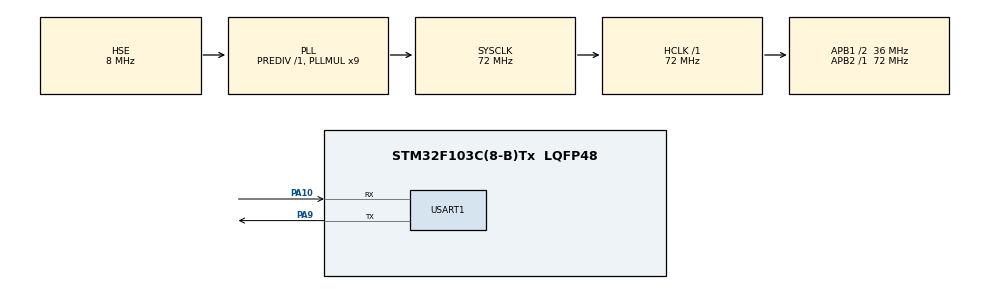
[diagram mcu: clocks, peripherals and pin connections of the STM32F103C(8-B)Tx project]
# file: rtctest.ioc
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Mcu.Family=STM32F1
Mcu.Name=STM32F103C(8-B)Tx
Mcu.Package=LQFP48
NVIC.PriorityGroup=NVIC_PRIORITYGROUP_4
PA10.Mode=Asynchronous
PA10.Signal=USART1_RX
PA13.Mode=Serial_Wire
PA13.Signal=SYS_JTMS-SWDIO
PA14.Mode=Serial_Wire
PA14.Signal=SYS_JTCK-SWCLK
PA9.Mode=Asynchronous
PA9.Signal=USART1_TX
PC14-OSC32_IN.Mode=LSE-External-Oscillator
PC14-OSC32_IN.Signal=RCC_OSC32_IN
PC15-OSC32_OUT.Mode=LSE-External-Oscillator
PC15-OSC32_OUT.Signal=RCC_OSC32_OUT
PD0-OSC_IN.Mode=HSE-External-Oscillator
PD0-OSC_IN.Signal=RCC_OSC_IN
PD1-OSC_OUT.Mode=HSE-External-Oscillator
PD1-OSC_OUT.Signal=RCC_OSC_OUT
ProjectManager.HeapSize=0x200
ProjectManager.StackSize=0x400
ProjectManager.TargetToolchain=STM32CubeIDE
RCC.AHBFreq_Value=72000000
RCC.APB1CLKDivider=RCC_HCLK_DIV2
RCC.APB1Freq_Value=36000000
RCC.APB1TimFreq_Value=72000000
RCC.APB2Freq_Value=72000000
RCC.APB2TimFreq_Value=72000000
RCC.HCLKFreq_Value=72000000
RCC.PLLMUL=RCC_PLL_MUL9
RCC.PLLSourceVirtual=RCC_PLLSOURCE_HSE
RCC.RTCClockSelection=RCC_RTCCLKSOURCE_LSE
RCC.SYSCLKFreq_VALUE=72000000
RCC.SYSCLKSource=RCC_SYSCLKSOURCE_PLLCLK
RCC.USBFreq_Value=72000000
USART1.VirtualMode=VM_ASYNC
VP_RTC_VS_RTC_Activate.Mode=RTC_Enabled
board=custom

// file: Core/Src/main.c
/* USER CODE BEGIN Header */
/**
  ******************************************************************************
  * @file           : main.c
  * @brief          : Main program body
  ******************************************************************************
  * @attention
  *
  * Copyright (c) 2025 STMicroelectronics.
  * All rights reserved.
  *
  * This software is licensed under terms that can be found in the LICENSE file
  * in the root directory of this software component.
  * If no LICENSE file comes with this software, it is provided AS-IS.
  *
  ******************************************************************************
  */
/* USER CODE END Header */
#include "main.h"

/* USER CODE BEGIN Includes */
#include <string.h>
#include <stdio.h>
#include <stdlib.h>
#include <time.h>
/* USER CODE END Includes */

/* USER CODE BEGIN PD */
#define UNIX_OFFSET 946702800UL
/* USER CODE END PD */

RTC_HandleTypeDef hrtc;

UART_HandleTypeDef huart1;

void SystemClock_Config(void);
static void MX_GPIO_Init(void);
static void MX_RTC_Init(void);
static void MX_USART1_UART_Init(void);
/* USER CODE BEGIN PFP */
HAL_StatusTypeDef MY_SetTimestamp(RTC_HandleTypeDef *hrtc, uint64_t ts);
/* USER CODE END PFP */

/* USER CODE BEGIN 0 */
#ifdef __GNUC__
  /* With GCC, small printf (option LD Linker->Libraries->Small printf
     set to 'Yes') calls __io_putchar() */
  #define PUTCHAR_PROTOTYPE int __io_putchar(int ch)
#else
  #define PUTCHAR_PROTOTYPE int fputc(int ch, FILE *f)
#endif /* __GNUC__ */
PUTCHAR_PROTOTYPE
{
  HAL_UART_Transmit(&huart1, (uint8_t *)&ch, 1, HAL_MAX_DELAY);
  return ch;
}

time_t MY_GetTimestamp(RTC_HandleTypeDef *hrtc)
{
    uint32_t counter = (uint32_t)hrtc->Instance->CNTH << 16 | (uint32_t)hrtc->Instance->CNTL;
    return (time_t)counter;
}

/* USER CODE END 0 */

int main(void)
{

  /* USER CODE BEGIN 1 */
   memset(&huart1, 0, sizeof(huart1));
  /* USER CODE END 1 */

  /* MCU Configuration--------------------------------------------------------*/

  /* Reset of all peripherals, Initializes the Flash interface and the Systick. */
  HAL_Init();

  /* Configure the system clock */
  SystemClock_Config();

  /* Initialize all configured peripherals */
  MX_GPIO_Init();
  MX_USART1_UART_Init();
  MX_RTC_Init();
  /* USER CODE BEGIN 2 */
  struct tm *my_tm = malloc(sizeof(struct tm));
  memset(my_tm, 0, sizeof(struct tm));
  printf("start\r\n");

  /* USER CODE END 2 */

  /* Infinite loop */
  /* USER CODE BEGIN WHILE */
  while (1)
  {

    time_t rtcCounter = MY_GetTimestamp(&hrtc);
    printf("ts:%lld\r\n", rtcCounter);
    my_tm = gmtime(&rtcCounter);
    printf("Date: %04d-%02d-%02d\r\n", my_tm->tm_year+1900, my_tm->tm_mon+1, my_tm->tm_mday);
    printf("Time: %02d:%02d:%02d\r\n", my_tm->tm_hour, my_tm->tm_min, my_tm->tm_sec);
    HAL_Delay(1000);
    /* USER CODE END WHILE */

  }
}

void SystemClock_Config(void)
{
  RCC_OscInitTypeDef RCC_OscInitStruct = {0};
  RCC_ClkInitTypeDef RCC_ClkInitStruct = {0};
  RCC_PeriphCLKInitTypeDef PeriphClkInit = {0};

  /** Initializes the RCC Oscillators according to the specified parameters
  * in the RCC_OscInitTypeDef structure.
  */
  RCC_OscInitStruct.OscillatorType = RCC_OSCILLATORTYPE_HSE|RCC_OSCILLATORTYPE_LSE;
  RCC_OscInitStruct.HSEState = RCC_HSE_ON;
  RCC_OscInitStruct.HSEPredivValue = RCC_HSE_PREDIV_DIV1;
  RCC_OscInitStruct.LSEState = RCC_LSE_ON;
  RCC_OscInitStruct.HSIState = RCC_HSI_ON;
  RCC_OscInitStruct.PLL.PLLState = RCC_PLL_ON;
  RCC_OscInitStruct.PLL.PLLSource = RCC_PLLSOURCE_HSE;
  RCC_OscInitStruct.PLL.PLLMUL = RCC_PLL_MUL9;
  if (HAL_RCC_OscConfig(&RCC_OscInitStruct) != HAL_OK)
  {
    Error_Handler();
  }

  /** Initializes the CPU, AHB and APB buses clocks
  */
  RCC_ClkInitStruct.ClockType = RCC_CLOCKTYPE_HCLK|RCC_CLOCKTYPE_SYSCLK
                              |RCC_CLOCKTYPE_PCLK1|RCC_CLOCKTYPE_PCLK2;
  RCC_ClkInitStruct.SYSCLKSource = RCC_SYSCLKSOURCE_PLLCLK;
  RCC_ClkInitStruct.AHBCLKDivider = RCC_SYSCLK_DIV1;
  RCC_ClkInitStruct.APB1CLKDivider = RCC_HCLK_DIV2;
  RCC_ClkInitStruct.APB2CLKDivider = RCC_HCLK_DIV1;

  if (HAL_RCC_ClockConfig(&RCC_ClkInitStruct, FLASH_LATENCY_2) != HAL_OK)
  {
    Error_Handler();
  }
  PeriphClkInit.PeriphClockSelection = RCC_PERIPHCLK_RTC;
  PeriphClkInit.RTCClockSelection = RCC_RTCCLKSOURCE_LSE;
  if (HAL_RCCEx_PeriphCLKConfig(&PeriphClkInit) != HAL_OK)
  {
    Error_Handler();
  }
}

static void MX_RTC_Init(void)
{

  /* USER CODE BEGIN RTC_Init 0 */
  HAL_PWR_EnableBkUpAccess();
  __HAL_RCC_BKP_CLK_ENABLE();
  __HAL_RCC_RTC_ENABLE();
  /* USER CODE END RTC_Init 0 */

  /** Initialize RTC Only
  */
  hrtc.Instance = RTC;
  hrtc.Init.AsynchPrediv = RTC_AUTO_1_SECOND;
  hrtc.Init.OutPut = RTC_OUTPUTSOURCE_ALARM;
  if (HAL_RTC_Init(&hrtc) != HAL_OK)
  {
    Error_Handler();
  }
  /* USER CODE BEGIN RTC_Init 2 */

  if (HAL_RTCEx_BKUPRead(&hrtc, RTC_BKP_DR1) != 0x4321) {
    MY_SetTimestamp(&hrtc, (time_t)1755715506);
    HAL_RTCEx_BKUPWrite(&hrtc, RTC_BKP_DR1, 0x4321);
  }

  /* USER CODE END RTC_Init 2 */

}

static void MX_USART1_UART_Init(void)
{

  /* USER CODE BEGIN USART1_Init 1 */
  huart1.gState = HAL_UART_STATE_RESET;
  /* USER CODE END USART1_Init 1 */
  huart1.Instance = USART1;
  huart1.Init.BaudRate = 115200;
  huart1.Init.WordLength = UART_WORDLENGTH_8B;
  huart1.Init.StopBits = UART_STOPBITS_1;
  huart1.Init.Parity = UART_PARITY_NONE;
  huart1.Init.Mode = UART_MODE_TX_RX;
  huart1.Init.HwFlowCtl = UART_HWCONTROL_NONE;
  huart1.Init.OverSampling = UART_OVERSAMPLING_16;
  if (HAL_UART_Init(&huart1) != HAL_OK)
  {
    Error_Handler();
  }

}

static void MX_GPIO_Init(void)
{

  /* GPIO Ports Clock Enable */
  __HAL_RCC_GPIOC_CLK_ENABLE();
  __HAL_RCC_GPIOD_CLK_ENABLE();
  __HAL_RCC_GPIOA_CLK_ENABLE();

}

void Error_Handler(void)
{
  __disable_irq();
  while (1)
  {
  }
}
